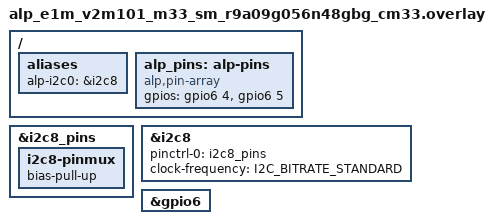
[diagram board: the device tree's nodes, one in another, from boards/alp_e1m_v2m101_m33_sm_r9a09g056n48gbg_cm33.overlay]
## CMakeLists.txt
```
# SPDX-License-Identifier: Apache-2.0

cmake_minimum_required(VERSION 3.20)

find_package(Zephyr REQUIRED HINTS $ENV{ZEPHYR_BASE})
project(v2n_cm33_deepx_rail LANGUAGES C)

target_sources(app PRIVATE src/main.c src/ca55_release.c)
```

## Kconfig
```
# Copyright (c) 2026 Alp Lab AB
# SPDX-License-Identifier: Apache-2.0

config V2N_CM33_BOOT_CONFIRMED
	bool "Acknowledge this image runs only on a cm33_boot unit"
	help
	  Without it main() refuses to master RIIC8 or touch P64/P65: in
	  a55_boot Linux also binds i2c8 and two masters can garble any PMIC
	  register.  power-tree.yaml cm33_boot is still `blocked`.  Replace
	  with a runtime BOOTSELCPU read (TODO alp-sdk#2289).

config V2N_CM33_RELEASE_CA55
	bool "Release CA55 core 0 after the DEEPX rail is up (CM33 cold boot only)"
	help
	  Calls v2n_cm33_release_ca55() once da9292_ch2_sequence() returned
	  ALP_OK.  Off by default: the AWO to ALL_ON entry it depends on is
	  still a TODO (alp-sdk#2289), so enabling it today only reaches the
	  fail-closed ALP_ERR_NOSUPPORT path.  Never enable on a CA55-cold-boot
	  unit (BOOTSELCPU high).

config V2N_CA55_BL2_ENTRY_ADDR
	hex "CA55 core 0 reset vector (RVBARADDR0) of the CM33-staged BL2"
	depends on V2N_CM33_RELEASE_CA55
	default 0x0
	help
	  Left at 0 on purpose: v2n_cm33_release_ca55() rejects it.  The staging
	  address of BL2 is not decided yet (alp-sdk#2289 bench steps 4 and 6).

source "Kconfig.zephyr"
```

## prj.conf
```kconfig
# SPDX-License-Identifier: Apache-2.0
#
# Feature-selection lives in board.yaml; this file is intentionally
# minimal.  Add app-specific tuning knobs here only when they are
# NOT board-/peripheral-selection (e.g. CONFIG_HEAP_MEM_POOL_SIZE).

CONFIG_PRINTK=y
CONFIG_LOG=y
```

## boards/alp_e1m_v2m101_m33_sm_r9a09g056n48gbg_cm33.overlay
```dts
/*
 * Copyright 2026 Alp Lab AB
 * SPDX-License-Identifier: Apache-2.0
 *
 * v2n-cm33-deepx-rail -- CM33-boot board overlay for the E1M-V2M101 EVK
 * (m33_sm cluster).  Re-enables what the DEFAULT AMP board configuration
 * (zephyr/boards/alp/e1m_v2m101_m33_sm/, CA55-cold-boot config) leaves
 * disabled for every other CM33 app: RIIC8 / BRD_I2C (&i2c8) and the
 * two DEEPX rail GPIOs, P64 (DEEPX_CORE_0P75_EN) and P65
 * (DEEPX_PWR_EN_REQ).
 *
 * Safe ONLY in cm33_boot mode, and ONLY before this app hands RIIC8 off
 * to the CA55 (power-tree.yaml boot_modes.cm33_boot is still `blocked`;
 * core-ownership.yaml still gives RIIC8 and P64/P65 to the A55, so this
 * overlay's claims are not recorded in metadata and
 * check_amp_pad_claims.py does not read project overlays).  RZ/V2N HW manual R01UH1071EJ0110 Rev.1.10 S1.9 Table
 * 1.9-1: BOOTSELCPU low = CM33 cold boot (this app's own boot mode),
 * high = CA55 cold boot (BOOTSELCPU is strapped on ACT88760 GPIO5 net
 * V2N_BOOT_CPU_SEL; the level-to-CPU mapping is TBD in power-tree.yaml).
 * In a55_boot mode, or after this app's own
 * handoff, the A55/Linux is the SOLE master of this bus -- building this
 * overlay into any OTHER CM33 app would be exactly the dual-master
 * hazard core-ownership.yaml's cross_check() exists to catch at the
 * metadata level (see scripts/gen_power_tree.py's _check_boot_modes()).
 *
 * The &i2c8 pinctrl group below does NOT just restore the pre-ownership-move
 * config verbatim: it also carries the two RIIC8/BRD_I2C fixes U-Boot's
 * board_late_init() needed to talk to this same bus reliably
 * (meta-alp-sdk/recipes-bsp/u-boot/u-boot/
 * 0006-rzv2n-dev-i2c-rzg2l_riic-p06-p07-pullup-clock-fix.patch;
 * changelog.d/2045-v2m-deepx-rail-uboot.md).  BRD_I2C is the
 * most heavily-loaded bus on the module (~13 populated branches):
 * external 2.2 kOhm pull-ups to the 1.8 V rail are fitted, and the
 * SoC-internal pull-up (bias-pull-up below) is bench-confirmed
 * ADDITIONALLY required at the faster (unpatched) clock, so both are
 * carried here too, same as 0006.  Standard-mode `clock-frequency`
 * (below) mirrors 0006's slower RIIC8 SCL (CKS(5)), bench-confirmed
 * needed for clean burst reads over this bus -- Fast mode (the
 * pre-ownership-move board file's setting) is what 0006 slowed down
 * FROM, not a value to restore.
 */

#include <zephyr/dt-bindings/gpio/gpio.h>
#include <zephyr/dt-bindings/i2c/i2c.h>

/ {
	aliases {
		alp-i2c0 = &i2c8;
	};

	/*
	 * P64 / P65 are SoM-internal DEEPX-sequencing pads, not E1M edge
	 * pins -- they carry no e1m_pinout.h canonical index, so this app's
	 * alp,pin-array is its OWN small 2-entry table (index 0 = P64,
	 * index 1 = P65), not the EVK's usual positional 30-entry array.
	 * This REPLACES the base board's 1-entry array (index 0 = the GD32
	 * SPI chip-select, P97/gpio9); this app never opens the GD32 SPI
	 * bus, so nothing else reads that index.  gpio6 = port 6 (P6n),
	 * following the same "gpio<port-digit>" pattern the base board
	 * file already uses for P97 (&gpio9).
	 */
	alp_pins: alp-pins {
		compatible = "alp,pin-array";
		gpios = <&gpio6 4 GPIO_ACTIVE_HIGH>,   /* [0] P64 DEEPX_CORE_0P75_EN (output) */
		        <&gpio6 5 GPIO_ACTIVE_HIGH>;   /* [1] P65 DEEPX_PWR_EN_REQ   (input)  */
	};
};

/*
 * RIIC8 / BRD_I2C -- P06 SDA / P07 SCL, DA9292 @ 0x1E (also GD32 slave @
 * 0x70, unused here).  Time-sliced to the CM33 in cm33_boot mode ONLY
 * (see the file header).  bias-pull-up enables the SoC-internal pull-up
 * on P06/P07 (matching U-Boot 0006's rzv2n-dev.c s_init() PUPD_H write
 * and what Linux's own i2c8_pins already sets) -- bench-confirmed
 * required at this bus's clock, on top of the external 2.2 kOhm
 * pull-ups already fitted.
 */
&i2c8_pins {
	i2c8-pinmux {
		bias-pull-up;
	};
};

&i2c8 {
	pinctrl-0 = <&i2c8_pins>;
	pinctrl-names = "default";
	/* Standard mode, not the pre-ownership-move board file's Fast mode:
	 * mirrors U-Boot 0006's RIIC8 clock slowdown (CKS(5)), bench-needed
	 * for clean reads over this heavily-loaded bus -- see the file
	 * header. */
	clock-frequency = <I2C_BITRATE_STANDARD>;
	status = "okay";
};

&gpio6 {
	status = "okay";
};
```

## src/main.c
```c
/*
 * Copyright 2026 Alp Lab AB
 * SPDX-License-Identifier: Apache-2.0
 *
 * v2n-cm33-deepx-rail -- sequence the DEEPX DX-M1 core rail (DA9292 CH2,
 * 0.75 V) from the CM33 system-manager, in CM33-boot mode.
 *
 * WHY THIS EXAMPLE EXISTS.  On the E1M-V2N / V2N-M1 SoM the boot-CPU is a
 * hardware strap: RZ/V2N pin BOOTSELCPU (RZ/V2N HW manual
 * R01UH1071EJ0110 Rev.1.10 Sec.1.9 Table 1.9-1) selects LOW = CM33 cold
 * boot, HIGH = CA55 cold boot, and is strapped on ACT88760 GPIO5 (net
 * V2N_BOOT_CPU_SEL; metadata/e1m_modules/v2n/power-tree.yaml).  Which GPIO5
 * level selects which CPU is not yet recorded there (TBD), so this app
 * states no power-on default.  In the DEFAULT (a55_boot) config, U-Boot's
 * board_late_init() (the 0004 patch) sequences this same rail on the A55 before releasing M1_RESET,
 * and CA55/Linux is thereafter the sole master of RIIC8/BRD_I2C -- see
 * metadata/e1m_modules/v2n/core-ownership.yaml.
 *
 * If BOOTSELCPU is instead strapped low, the CM33 cold-boots FIRST (from
 * xSPI or SCIF download -- the only two boot sources CM33-cold-boot
 * supports) and must release the CA55 itself, later.  THIS app is what
 * runs during that window: it masters RIIC8 and programs the DA9292
 * exactly like U-Boot 0004 does, using the SAME portable chip-driver
 * function (da9292_ch2_sequence(), <alp/chips/da9292.h>) so the two paths
 * can never drift apart.  Ownership is TIME-SLICED, never concurrent --
 * this app's window ends (the CA55 release at the bottom) BEFORE the CA55
 * starts, at which point U-Boot 0004 runs again as a warm, idempotent
 * VERIFY (its program phase is a no-op when CH2 is already at target).
 * METADATA STATUS.  power-tree.yaml `boot_modes.cm33_boot` is still
 * `status: blocked` and core-ownership.yaml still says the CM33 must not
 * master RIIC8 or claim P64/P65 (standing 2026-09-24 decision).  This
 * example does NOT unblock that; it needs a maintainer re-decision plus the
 * full slice power-tree.yaml lists.  Until then it fails closed: it refuses
 * to touch RIIC8 unless CONFIG_V2N_CM33_BOOT_CONFIRMED is set.
 * TODO(alp-sdk#2289): replace that build-time acknowledgement with a
 * runtime BOOTSELCPU read once the register is cited from the HW manual.
 *
 * DO NOT wire this app's board overlay into any OTHER CM33 example: it
 * re-enables &i2c8, which every other CM33 app must leave disabled
 * (RIIC8/BRD_I2C is Cortex-A55/Linux-exclusive outside this one window).
 */

#include <stdio.h>

#include "alp/peripheral.h"
#include "alp/chips/da9292.h"
#include "alp/chips/v2n_power_tree.h"
#include "ca55_release.h"

/* alp,pin-array indices this app's board overlay defines (see
 * boards/alp_e1m_v2m101_m33_sm_r9a09g056n48gbg_cm33.overlay) -- NOT the
 * usual E1M positional pinout, since P64/P65 are SoM-internal pads. */
#define PIN_ID_DEEPX_CORE_0P75_EN 0u /* P64, output */
#define PIN_ID_DEEPX_PWR_EN_REQ   1u /* P65, input  */

/* Zephyr delay callback for da9292_ch2_sequence() -- keeps the driver
 * OS-agnostic (Linux/U-Boot pass their own wrappers around the same
 * function pointer type). Wraps the portable alp_delay_us() (Zephyr
 * backend: k_busy_wait()/k_usleep() depending on duration) rather than
 * calling a Zephyr kernel API directly, so this app stays inside the
 * portable alp headers end to end. */
static void zephyr_delay_us(void *user, uint32_t us)
{
	(void)user;
	alp_delay_us(us);
}

/* Human-readable name for a da9292_ch2_seq_step_t -- every abort path the
 * driver can take, so a console-attached run always says exactly where it
 * stopped instead of just a bare error code. */
static const char *step_name(da9292_ch2_seq_step_t step)
{
	switch (step) {
	case DA9292_SEQ_OK:
		return "OK";
	case DA9292_SEQ_ERR_ARGS:
		return "bad cfg / no limits table / target outside window";
	case DA9292_SEQ_ERR_IDENTITY:
		return "PMC_DEV_ID mismatch or unreadable";
	case DA9292_SEQ_ERR_STATUS01:
		return "PMC_STATUS_01 != 0x00 (thermal/UVLO latched)";
	case DA9292_SEQ_ERR_PREREAD:
		return "CTRL_01 / VOUT pre-program read failed";
	case DA9292_SEQ_ERR_CLEAR_VSTEP:
		return "VSTEP+EN clear write/read-back failed";
	case DA9292_SEQ_ERR_PROGRAM_VOUT:
		return "VOUT_CH2 program write/read-back failed";
	case DA9292_SEQ_ERR_CH1_DISTURBED:
		return "CH1 VOUT changed or CH1_EN cleared";
	case DA9292_SEQ_ERR_EVENTS:
		return "EVENT_00/01 pre-clear read failed";
	case DA9292_SEQ_ERR_NO_REQUEST:
		return "DEEPX_PWR_EN_REQ (P65) never went high";
	case DA9292_SEQ_ERR_VSTEP_AT_ENABLE:
		return "CH2_VSTEP set right before enable";
	case DA9292_SEQ_ERR_ENABLE:
		return "CH2_EN write failed";
	case DA9292_SEQ_ERR_PG_TIMEOUT:
		return "no CH2_PG (or a fault) within the timeout";
	case DA9292_SEQ_ERR_PG_DROPPED:
		return "PG lost after DEEPX_CORE_0P75_EN went high";
	default:
		return "unknown step";
	}
}

int main(void)
{
	printf("[cm33-deepx-rail] V2N-M1 CM33-boot DEEPX 0.75V rail sequencer\n");
#if !defined(CONFIG_V2N_CM33_BOOT_CONFIRMED)
	/* Fail closed: in a55_boot Linux also binds i2c8, and a second RIIC8
	 * master can garble any PMIC register.  No RIIC8/P64/P65 access. */
	printf("[cm33-deepx-rail] refusing to master RIIC8: set CONFIG_V2N_CM33_BOOT_CONFIRMED "
	       "only on a unit strapped for cm33_boot (see the file header)\n");
	return 0;
#endif
	printf("[cm33-deepx-rail] this app is ONLY correct if BOOTSELCPU strapped this boot "
	       "as cm33_boot -- see the file header if you are not sure\n");

	/* BRD_I2C / RIIC8: this app's board overlay is the ONLY thing that
	 * enables &i2c8 for a CM33 build on this SoM -- see its header.
	 * ALP_I2C_CONFIG_DEFAULT's 100 kHz standard-mode bitrate is kept
	 * as-is (not raised to Fast): alp_i2c_open() calls i2c_configure()
	 * at runtime, which would otherwise override the overlay's
	 * I2C_BITRATE_STANDARD and undo the slower RIIC8 clock this bus
	 * bench-needs (see the overlay header, mirrors U-Boot 0006's
	 * CKS(5)). */
	alp_i2c_config_t i2c_cfg = ALP_I2C_CONFIG_DEFAULT(0);
	alp_i2c_t       *i2c     = alp_i2c_open(&i2c_cfg);
	if (i2c == NULL) {
		printf("[cm33-deepx-rail] alp_i2c_open failed: err=%d -- check the board "
		       "overlay enables &i2c8\n",
		       (int)alp_last_error());
		return 0;
	}

	/* P64 DEEPX_CORE_0P75_EN: output, start low (rail stays down until
	 * the sequence below confirms CH2 power-good).  Write false BEFORE
	 * configure, then again after -- the same write-before-configure-
	 * then-write-after pattern chips/tas2563/tas2563.c's SD_N handling
	 * uses (see the long comment above its `if (sd_n != NULL)` block)
	 * for the identical reason: `alp_gpio_configure(..., ALP_GPIO_OUTPUT,
	 * ...)` deliberately does not force a level (see `_to_gpio_flags()`,
	 * src/backends/gpio/zephyr_drv.c), so on a backend whose direction
	 * switch alone can glitch the data register, only a write already in
	 * flight before that switch closes the window; the second write
	 * covers a backend (gpio_emul among them) that drops a write issued
	 * before the pin is configured as output. */
	alp_gpio_t  *core_en = alp_gpio_open(PIN_ID_DEEPX_CORE_0P75_EN);
	alp_status_t s       = ALP_ERR_NOT_READY;
	if (core_en != NULL) {
		s = alp_gpio_write(core_en, false);
		if (s == ALP_OK) s = alp_gpio_configure(core_en, ALP_GPIO_OUTPUT, ALP_GPIO_PULL_NONE);
		if (s == ALP_OK) s = alp_gpio_write(core_en, false);
	}
	if (s != ALP_OK) {
		printf("[cm33-deepx-rail] P64 (DEEPX_CORE_0P75_EN) open/configure failed: %d\n", (int)s);
		goto out_core_en; /* alp_gpio_close(NULL) is a safe no-op if open() itself failed */
	}

	/* P65 DEEPX_PWR_EN_REQ: input, no pull -- the DEEPX power-enable
	 * request, polled by da9292_ch2_sequence(). */
	alp_gpio_t *pwr_en_req = alp_gpio_open(PIN_ID_DEEPX_PWR_EN_REQ);
	s = (pwr_en_req != NULL) ? alp_gpio_configure(pwr_en_req, ALP_GPIO_INPUT, ALP_GPIO_PULL_NONE)
	                         : ALP_ERR_NOT_READY;
	if (s != ALP_OK) {
		printf("[cm33-deepx-rail] P65 (DEEPX_PWR_EN_REQ) open/configure failed: %d\n", (int)s);
		goto out_pwr_en_req; /* alp_gpio_close(NULL) is a safe no-op if open() itself failed */
	}

	/* da9292_init() only probes PMC_DEV_ID -- no register write yet. */
	da9292_t ctx;
	s = da9292_init(&ctx, i2c, DA9292_I2C_ADDR_V2N);
	if (s != ALP_OK) {
		printf("[cm33-deepx-rail] da9292_init failed: %d (DA9292 not answering on "
		       "BRD_I2C?)\n",
		       (int)s);
		goto out_pwr_en_req;
	}

	/* Unlocks every guarded write; da9292_ch2_sequence() refuses
	 * (ALP_ERR_NOSUPPORT) with none installed.  V2M101 is v2n-m1 family.
	 * The generated macro is a brace-init-list (array initializer), not
	 * a pointer -- static storage per da9292_set_limits()'s contract:
	 * ch_limits must outlive ctx. */
	static const pmic_rail_limit_t da9292_ch_limits[DA9292_CH_COUNT] =
	    V2N_M1_POWER_DA9292_CH_LIMITS_INIT;
	s = da9292_set_limits(&ctx, da9292_ch_limits);
	if (s != ALP_OK) {
		printf("[cm33-deepx-rail] da9292_set_limits failed: %d\n", (int)s);
		goto out_pwr_en_req;
	}

	/* Mirrors U-Boot 0004's alp_deepx_rail_bringup() step for step -- see
	 * da9292_ch2_sequence()'s doc comment for the full 13-step walk. */
	struct da9292_ch2_seq_cfg cfg = {
		.target_mv = 750u,
		/* One shared identity macro across both families -- see
		 * v2n_power_tree.h: DEV_ID/REV_ID/CFG_REV are emitted once,
		 * prefixed from families[0] ("v2n") regardless of which
		 * family's *_CH_LIMITS_INIT table is in use below. */
		.expected_dev_id = V2N_POWER_DA9292_DEV_ID,
		.pwr_en_req      = pwr_en_req,
		.core_en         = core_en,
		.m1_reset        = NULL, /* PCIe bring-up releases M1_RESET, not this app */
		.req_timeout_ms  = 500u,
		.pg_timeout_ms   = 20u,
		.pg_settle_ms    = 5u,
		.delay           = zephyr_delay_us,
		.delay_user      = NULL,
	};
	struct da9292_ch2_seq_result res;
	s = da9292_ch2_sequence(&ctx, &cfg, &res);

	printf("[cm33-deepx-rail] da9292_ch2_sequence -> %d, step=%s%s\n",
	       (int)s,
	       step_name(res.step),
	       res.already_programmed ? " (warm: already at target, program phase skipped)" : "");
	if (s == ALP_OK) {
		printf("[cm33-deepx-rail] VDD_0P75 up, rail_up=%d, CH2_PG confirmed, "
		       "DEEPX_CORE_0P75_EN (P64) high\n",
		       (int)res.rail_up);
	} else {
		printf("[cm33-deepx-rail] rail sequence FAILED -- status_00=0x%02x status_01=0x%02x "
		       "event_00=0x%02x ctrl_01=0x%02x\n",
		       res.status_00,
		       res.status_01,
		       res.event_00,
		       res.ctrl_01);
	}

	/*
	 * CA55 release (alp-sdk#2289).  Only on ALP_OK: a rail failure leaves
	 * the CA55 held.  This app masters RIIC8 only until this handoff
	 * -- release the bus users in the order below: close the
	 * I2C/GPIO handles first, so nothing of ours touches RIIC8 once the CA55
	 * (U-Boot 0004's idempotent verify pass, then Linux) can.  Default off:
	 * the helper still lacks the AWO->ALL_ON entry, see ca55_release.c.
	 */
#if defined(CONFIG_V2N_CM33_RELEASE_CA55)
	if (s == ALP_OK) {
		alp_gpio_close(pwr_en_req);
		alp_gpio_close(core_en);
		alp_i2c_close(i2c);
		pwr_en_req = NULL;
		core_en    = NULL;
		i2c        = NULL;
		s          = v2n_cm33_release_ca55(CONFIG_V2N_CA55_BL2_ENTRY_ADDR);
		printf("[cm33-deepx-rail] v2n_cm33_release_ca55 -> %d\n", (int)s);
		return 0; /* handles already closed above */
	}
#else
	printf("[cm33-deepx-rail] CA55 release disabled (CONFIG_V2N_CM33_RELEASE_CA55=n); "
	       "stopping here\n");
#endif

out_pwr_en_req:
	alp_gpio_close(pwr_en_req);
out_core_en:
	alp_gpio_close(core_en);
	alp_i2c_close(i2c); /* no separate out_i2c: label -- nothing jumps here directly */
	printf("[cm33-deepx-rail] done\n");
	return 0;
}
```

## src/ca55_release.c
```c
/*
 * Copyright 2026 Alp Lab AB
 * SPDX-License-Identifier: Apache-2.0
 *
 * v2n_cm33_release_ca55() -- start CA55 core 0 from the CM33 (alp-sdk#2289).
 *
 * DECISION (issue #2289).  In CM33 cold boot only PD_AWO is powered and the
 * CA55 cluster stays in reset.  The CM33 releases core 0 itself, after the
 * DEEPX rail sequence, with the reset vector pointed at a CM33-staged TF-A
 * BL2 through SYS_ACPU_CFG_RVAL0/RVAH0.  BL2 keeps training DDR as today and
 * no OTP is involved.
 *
 * SOURCE OF THE REGISTER FACTS.  The RZ/V2N FSP / hal_renesas headers
 * (cpg_iodefine.h, sysc_iodefine.h) are NOT in this tree, so nothing below
 * can cite a header line.  Every offset and bit field is taken verbatim from
 * the alp-sdk#2289 comment that re-checked them against the RZ/V2N hardware
 * manual R01UH1071EJ0120 Rev.1.20: S4.3 Table 4.3-1 / S4.4 Table 4.4-4
 * (bases), S4.3.3.2.89-90 (RVAL0/RVAH0), S4.4.4.11 (CPG_RST_m), S4.4.4.22
 * (CPG_LP_CA55_CTL1), S4.4.4.23 (CPG_LP_CA55_CTL2), S2.2.2.2.1 Table 2.2-7
 * (cold-reset release, software control by the CM33).
 * TODO(alp-sdk#2289): cross-check every constant against the FSP headers
 * before the first bench run; nothing here has run on silicon.
 *
 * UNVERIFIED: the CM33 security state and whether CPG/SYS reset control is
 * writable from non-secure.  The _NS aliases below are an assumption (the
 * board file uses _NS MHU bases, which proves nothing about CPG/SYS), and
 * tests/scripts/test_provision_uboot.py:123 uses SYS at 0x10430000.
 * TODO(alp-sdk#2289): cite the manual table row for the 0x5042xxxx /
 * 0x5043xxxx aliases and the CPG access attribute.
 */

#include <zephyr/arch/cpu.h>

#include "ca55_release.h"

/* TODO(alp-sdk#2289): NS alias unverified (see file header). */
#define CPG_BASE_NS 0x50420000UL /* S4.4 Table 4.4-4 */
#define SYS_BASE_NS 0x50430000UL /* S4.3 Table 4.3-1 */

/* Offsets/bits below: S4.3.3.2.89-90 (RVAL0/RVAH0), S4.4.4.11 (CPG_RST_m),
 * S4.4.4.22 (CPG_LP_CA55_CTL1), S4.4.4.23 (CPG_LP_CA55_CTL2).  Taken from the
 * issue comment; TODO(alp-sdk#2289): confirm each bit row vs the manual/FSP. */

#define SYS_ACPU_CFG_RVAL0 (SYS_BASE_NS + 0x0624UL) /* [31:2] = RVBARADDR[31:2] */
#define SYS_ACPU_CFG_RVAH0 (SYS_BASE_NS + 0x0628UL) /* [7:0]  = RVBARADDR[39:32] */

/* CPG_RST_m = CPG + 0900h + m*4.  1b = reset off.  Bits [31:16] are per-bit
 * write enables (RSTBn_WEN): only bits whose enable is set change.  Table
 * 4.4-22 puts CA55_RESET0..13 in RST_0 and CA55_RESET14..16 in RST_1. */
#define CPG_RST(m)     (CPG_BASE_NS + 0x0900UL + (uint32_t)(m) * 4UL)
#define RST0_CA55_MASK 0x00003FFFUL /* RSTB[13:0] */
#define RST1_CA55_MASK 0x00000007UL /* RSTB[2:0]  */
#define RST_WEN(mask)  ((mask) << 16)

#define CPG_LP_CA55_CTL1 (CPG_BASE_NS + 0x0C20UL)
#define CTL1_CLUSTERPREQ (1UL << 0)
#define CTL1_PSTATE_POS  1u
#define CTL1_PSTATE_MASK (0x7FUL << CTL1_PSTATE_POS)
#define CTL1_PSTATE_ON   0x48UL /* CLUSTERPSTATE: 48h = ON */
#define CTL1_PDENY       (1UL << 8)
#define CTL1_PACCEPT     (1UL << 9)

#define CPG_LP_CA55_CTL2 (CPG_BASE_NS + 0x0C24UL)
#define CTL2_COREPREQ0   (1UL << 0)
#define CTL2_PSTATE_POS  1u
#define CTL2_PSTATE_MASK (0x3FUL << CTL2_PSTATE_POS)
#define CTL2_PSTATE_ON   0x08UL /* COREPSTATE0: 08h = ON */
#define CTL2_PDENY       (1UL << 7)
#define CTL2_PACCEPT     (1UL << 8)

#define POLL_STEP_US 100u
#define POLL_MAX     1000u /* 100 ms per poll */

static uint32_t rd(uintptr_t addr)
{
	return sys_read32(addr);
}

static void wr(uintptr_t addr, uint32_t v)
{
	sys_write32(v, addr);
}

/* Read-modify-write: the manual's `*` bits must be preserved. */
static void rmw(uintptr_t addr, uint32_t clear, uint32_t set)
{
	wr(addr, (rd(addr) & ~clear) | set);
}

/* Bounded poll until (reg & mask) == want.  Never spins forever. */
static alp_status_t poll(uintptr_t addr, uint32_t mask, uint32_t want)
{
	for (uint32_t i = 0; i < POLL_MAX; i++) {
		if ((rd(addr) & mask) == want) return ALP_OK;
		alp_delay_us(POLL_STEP_US);
	}
	return ALP_ERR_TIMEOUT;
}

/*
 * TODO(alp-sdk#2289): AWO -> ALL_ON entry, HW manual S4.5.3.1.1 Table 4.5-4.
 * PD_OTHERS / PD_CA55 / PD_DDR0 are NOT powered in CM33 cold boot, so the
 * release below hangs or faults without it.  The issue lists the steps
 * (CPG_RST_n assert, CPG_OTHERS_INI.OTHERS_RST, CPG_LP_PWC_CTL1.OTHERS_ON_TRG,
 * CPG_LP_PWC_CTL2.PWEN poll, CPG_BUS_12_MSTOP, CPG_*_STBY / CPG_PLL*_MON,
 * CPG_LP_PMU_CTL1, OTP_HANDSHAKE_MON.DFT_DONE) but gives NO offsets for those
 * registers, and they are not in the tree.  Not guessed: this returns
 * ALP_ERR_NOSUPPORT so v2n_cm33_release_ca55() fails closed with the CA55
 * held until the offsets are taken from the manual / FSP headers.
 */
static alp_status_t all_on_entry(void)
{
	return ALP_ERR_NOSUPPORT;
}

alp_status_t v2n_cm33_release_ca55(uint64_t entry_addr)
{
	/* RVAL0[1:0] read 0 (4-byte aligned); RVAH0 carries only bits 39:32. */
	if (entry_addr == 0u || (entry_addr & 0x3u) != 0u || (entry_addr >> 40) != 0u)
		return ALP_ERR_INVAL;

	/* Table 4.5-4: PD_OTHERS / PD_CA55 / PD_DDR0 on, before anything below. */
	alp_status_t s = all_on_entry();
	if (s != ALP_OK) return s;

	/* The vector is sampled when reset is applied, so stage it first.  Do
	 * not rely on the OTP default: write RVAL0/RVAH0 explicitly (the manual
	 * does not say which wins when they are left unwritten; bench step 5). */
	wr(SYS_ACPU_CFG_RVAL0, (uint32_t)(entry_addr & 0xFFFFFFFCu));
	wr(SYS_ACPU_CFG_RVAH0, (uint32_t)(entry_addr >> 32));

	/* Table 2.2-7 (CM33 software control), read-modify-write throughout.
	 * Cluster, then core 0: state = ON and request. */
	rmw(CPG_LP_CA55_CTL1, CTL1_PSTATE_MASK, (CTL1_PSTATE_ON << CTL1_PSTATE_POS) | CTL1_CLUSTERPREQ);
	rmw(CPG_LP_CA55_CTL2, CTL2_PSTATE_MASK, (CTL2_PSTATE_ON << CTL2_PSTATE_POS) | CTL2_COREPREQ0);

	/* Reset release: RST_1 first, then RST_0, RSTB = 1 with their WEN bits. */
	wr(CPG_RST(1), RST_WEN(RST1_CA55_MASK) | RST1_CA55_MASK);
	/* TODO(alp-sdk#2289): the table polls CPG_RSTMON_0 (CPG+0A00h) here and
	 * after the RST_0 write, "= 0 for the CA55 bits".  The issue gives the
	 * offset but not the CA55 bit mask, so the polls are omitted rather than
	 * guessed; the ACCEPT polls below are the only completion check. */
	wr(CPG_RST(0), RST_WEN(RST0_CA55_MASK) | RST0_CA55_MASK);

	/* From here the CA55 is running, so a failure can no longer re-hold it;
	 * drop the requests on the way out and report. */
	s = poll(CPG_LP_CA55_CTL1, CTL1_PACCEPT | CTL1_PDENY, CTL1_PACCEPT);
	if (s == ALP_OK) s = poll(CPG_LP_CA55_CTL2, CTL2_PACCEPT | CTL2_PDENY, CTL2_PACCEPT);
	if (s != ALP_OK && ((rd(CPG_LP_CA55_CTL1) & CTL1_PDENY) || (rd(CPG_LP_CA55_CTL2) & CTL2_PDENY)))
		s = ALP_ERR_IO;

	rmw(CPG_LP_CA55_CTL1, CTL1_CLUSTERPREQ, 0u);
	rmw(CPG_LP_CA55_CTL2, CTL2_COREPREQ0, 0u);
	if (s == ALP_OK) s = poll(CPG_LP_CA55_CTL1, CTL1_PACCEPT, 0u);
	if (s == ALP_OK) s = poll(CPG_LP_CA55_CTL2, CTL2_PACCEPT, 0u);
	return s;
}
```

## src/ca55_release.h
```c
/*
 * Copyright 2026 Alp Lab AB
 * SPDX-License-Identifier: Apache-2.0
 *
 * v2n_cm33_release_ca55() -- CM33-side release of CA55 core 0 on the RZ/V2N
 * in CM33 cold boot (BOOTSELCPU low).  See ca55_release.c for the register
 * facts, their source, and what is still a TODO.
 */
#ifndef V2N_CA55_RELEASE_H
#define V2N_CA55_RELEASE_H

#include <stdint.h>

#include "alp/peripheral.h"

/**
 * @brief Release CA55 core 0 from reset with its reset vector at @p entry_addr.
 *
 * Call ONLY after da9292_ch2_sequence() returned ALP_OK: a rail failure must
 * leave the CA55 held, and that gate is the caller's job.  The image at
 * @p entry_addr (CM33-staged TF-A BL2 in SRAM2 or DDR) must already be in
 * place; this function neither copies nor verifies it.
 *
 * Fails closed: every error before the CPG reset-release writes leaves the
 * CA55 held.  Errors after them cannot re-hold a running core.
 *
 * @param entry_addr  40-bit CA55 reset vector (RVBARADDR0), 4-byte aligned,
 *                    non-zero.
 * @retval ALP_OK             Cluster and core 0 accepted the power request.
 * @retval ALP_ERR_INVAL      @p entry_addr zero, unaligned or above 40 bits.
 * @retval ALP_ERR_NOSUPPORT  The PD_OTHERS/PD_CA55/PD_DDR0 AWO to ALL_ON entry
 *                            is not implemented yet (see the TODO); nothing
 *                            was written.
 * @retval ALP_ERR_TIMEOUT    A bounded poll expired.
 * @retval ALP_ERR_IO         The cluster or core denied the power request.
 */
alp_status_t v2n_cm33_release_ca55(uint64_t entry_addr);

#endif /* V2N_CA55_RELEASE_H */
```
